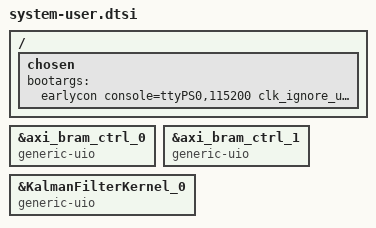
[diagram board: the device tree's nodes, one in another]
/include/ "system-conf.dtsi"
/ {
    chosen { 
        bootargs = "earlycon console=ttyPS0,115200 clk_ignore_unused root=/dev/mmcblk0p2 rw rootwait cma=512M uio_pdrv_genirq.of_id=generic-uio"; 
    };
};

// Custom IP map to UIO
&axi_bram_ctrl_0{
	compatible = "generic-uio";
	};
&axi_bram_ctrl_1{
	compatible = "generic-uio";
	};
&KalmanFilterKernel_0{
	compatible = "generic-uio";
	};
